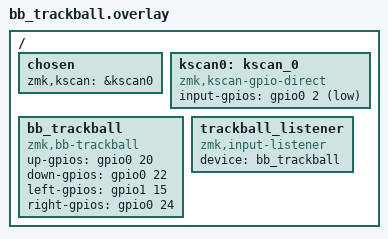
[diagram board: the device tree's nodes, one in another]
/ {
    chosen {
        zmk,kscan = &kscan0;
    };

    /* Single key kscan just for the click button */
    kscan0: kscan_0 {
        compatible = "zmk,kscan-gpio-direct";
        input-gpios = <&gpio0 2 (GPIO_ACTIVE_LOW | GPIO_PULL_UP)>;
    };

    /* Trackball movement via edge-triggered GPIO interrupts */
    bb_trackball: bb_trackball {
        compatible = "zmk,bb-trackball";
        up-gpios    = <&gpio0 20 0>;
        down-gpios  = <&gpio0 22 0>;
        left-gpios  = <&gpio1 15 0>;
        right-gpios = <&gpio0 24 0>;
    };

    trackball_listener: trackball_listener {
        compatible = "zmk,input-listener";
        device = <&bb_trackball>;
    };
};
